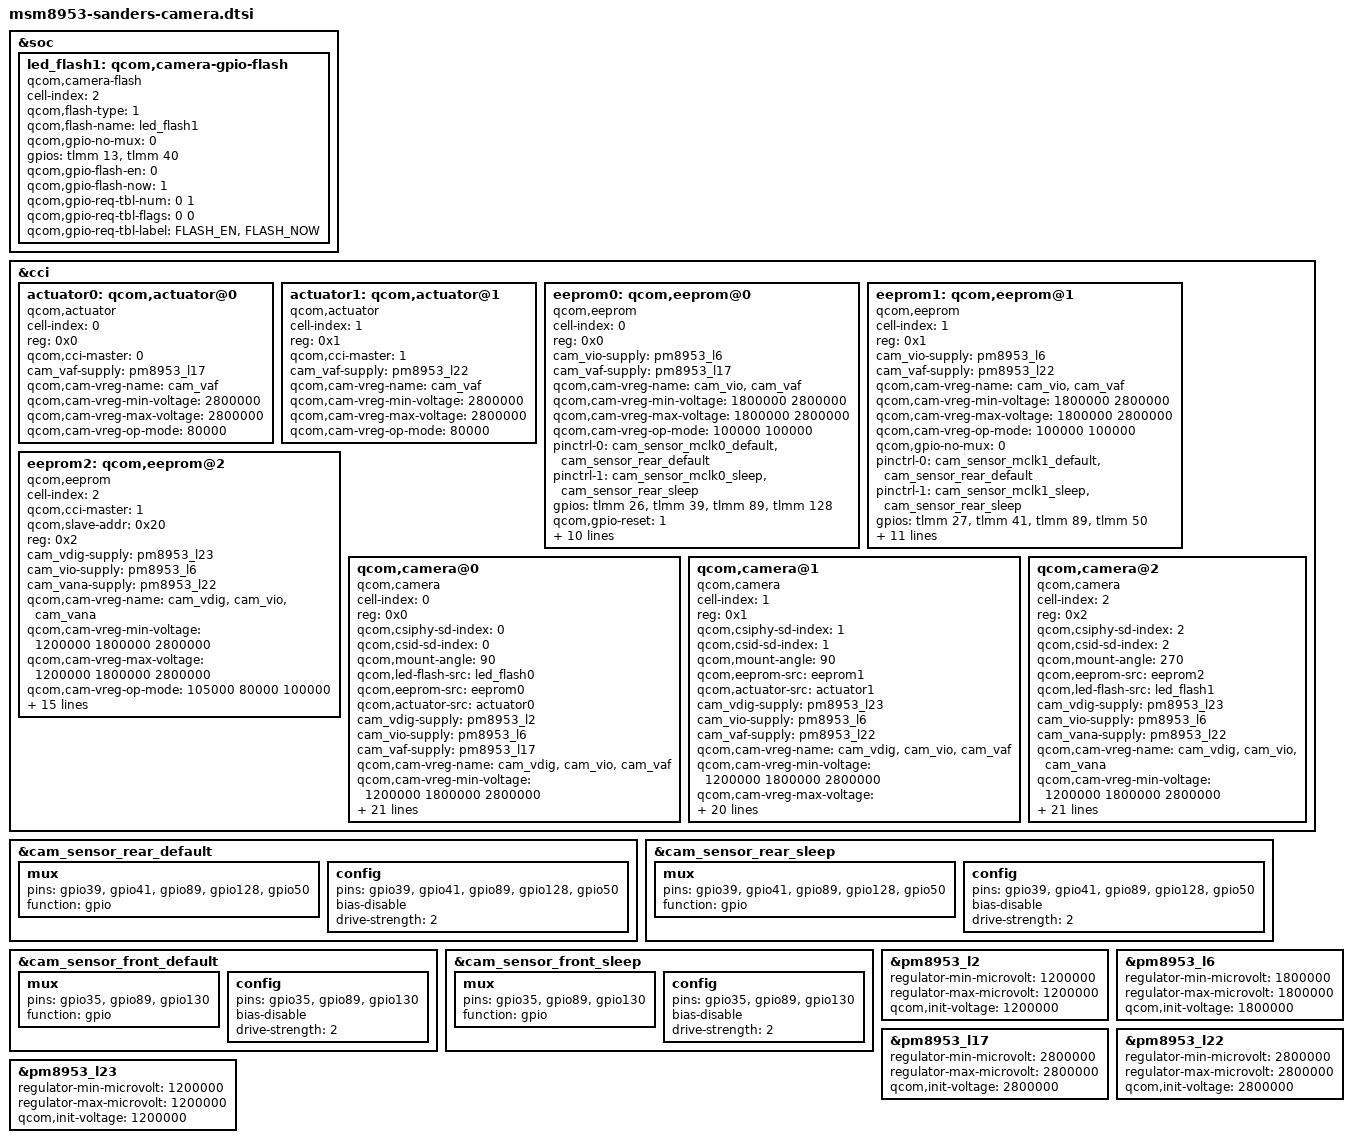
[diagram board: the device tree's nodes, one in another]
/*
 * Copyright (c) 2015-2016, The Linux Foundation. All rights reserved.
 *
 * This program is free software; you can redistribute it and/or modify
 * it under the terms of the GNU General Public License version 2 and
 * only version 2 as published by the Free Software Foundation.
 *
 * This program is distributed in the hope that it will be useful,
 * but WITHOUT ANY WARRANTY; without even the implied warranty of
 * MERCHANTABILITY or FITNESS FOR A PARTICULAR PURPOSE.  See the
 * GNU General Public License for more details.
 */

/*
 * Moto G5S Plus (sanders) cameras, ported from the Motorola 3.18
 * msm8953-camera-sensor-mot-sanders.dtsi to the 4.9 camera_v2 bindings:
 *   - rear:  2x S5K3L8 (bayer + mono) with actuators and eeproms
 *   - front: S5K4H8 with eeprom and a GPIO flash
 *   - rear flash: PMI8950 flash LEDs (led_flash0 from pmi8950.dtsi)
 *
 * Binding differences vs 3.18:
 *   - The CCI controller node comes from msm8953-camera.dtsi (identical).
 *   - The front GPIO flash used the Moto-only "qcom,camera-gpio-flash"
 *     driver. In 4.9 msm_flash.c handles GPIO flashes itself (driver type
 *     FLASH_DRIVER_GPIO when no PMIC source is given), so the node uses
 *     compatible "qcom,camera-flash" with qcom,gpio-flash-en/-now.
 *   - Camera pin groups already exist in msm8953-pinctrl.dtsi with
 *     different pins; only their pin lists are overridden here.
 */

&soc {
	led_flash1: qcom,camera-gpio-flash {
		cell-index = <2>;
		compatible = "qcom,camera-flash";
		qcom,flash-type = <1>;
		qcom,flash-name = "led_flash1";
		qcom,gpio-no-mux = <0>;
		gpios = <&tlmm 13 0>,
			<&tlmm 40 0>;
		qcom,gpio-flash-en = <0>;
		qcom,gpio-flash-now = <1>;
		qcom,gpio-req-tbl-num = <0 1>;
		qcom,gpio-req-tbl-flags = <0 0>;
		qcom,gpio-req-tbl-label = "FLASH_EN",
			"FLASH_NOW";
	};
};

&cci {
	#address-cells = <1>;
	#size-cells = <0>;

	actuator0: qcom,actuator@0 {
		cell-index = <0>;
		reg = <0x0>;
		compatible = "qcom,actuator";
		qcom,cci-master = <0>;
		cam_vaf-supply = <&pm8953_l17>;
		qcom,cam-vreg-name = "cam_vaf";
		qcom,cam-vreg-min-voltage = <2800000>;
		qcom,cam-vreg-max-voltage = <2800000>;
		qcom,cam-vreg-op-mode = <80000>;
	};

	actuator1: qcom,actuator@1 {
		cell-index = <1>;
		reg = <0x1>;
		compatible = "qcom,actuator";
		qcom,cci-master = <1>;
		cam_vaf-supply = <&pm8953_l22>;
		qcom,cam-vreg-name = "cam_vaf";
		qcom,cam-vreg-min-voltage = <2800000>;
		qcom,cam-vreg-max-voltage = <2800000>;
		qcom,cam-vreg-op-mode = <80000>;
	};

	/* S5K3L8 BEAR EEPROM*/
	eeprom0: qcom,eeprom@0 {
		cell-index = <0>;
		reg = <0x0>;
		compatible = "qcom,eeprom";
		cam_vio-supply = <&pm8953_l6>;
		cam_vaf-supply = <&pm8953_l17>;
		qcom,cam-vreg-name = "cam_vio", "cam_vaf";
		qcom,cam-vreg-min-voltage = <1800000 2800000>;
		qcom,cam-vreg-max-voltage = <1800000 2800000>;
		qcom,cam-vreg-op-mode = <100000 100000>;
		pinctrl-names = "cam_default", "cam_suspend";
		pinctrl-0 = <&cam_sensor_mclk0_default
				&cam_sensor_rear_default>;
		pinctrl-1 = <&cam_sensor_mclk0_sleep &cam_sensor_rear_sleep>;
		gpios = <&tlmm 26 0>,
			<&tlmm 39 0>,
			<&tlmm 89 0>,
			<&tlmm 128 0>;
		qcom,gpio-reset = <1>;
		qcom,gpio-vio = <2>;
		qcom,gpio-vana = <3>;
		qcom,gpio-req-tbl-num = <0 1 2 3>;
		qcom,gpio-req-tbl-flags = <1 0 0 0>;
		qcom,gpio-req-tbl-label = "CAMIF_MCLK0",
			"CAM_RESET0",
			"CAM_IO0",
			"CAM_VANA0";
		qcom,cci-master = <0>;
		status = "ok";
		clocks = <&clock_gcc clk_mclk0_clk_src>,
				<&clock_gcc clk_gcc_camss_mclk0_clk>;
		clock-names = "cam_src_clk", "cam_clk";
		qcom,clock-rates = <24000000 0>;
	};

	/* S5K3L8 MONO EEPROM */
	eeprom1: qcom,eeprom@1 {
		cell-index = <1>;
		reg = <0x1>;
		compatible = "qcom,eeprom";
		cam_vio-supply = <&pm8953_l6>;
		cam_vaf-supply = <&pm8953_l22>;
		qcom,cam-vreg-name = "cam_vio", "cam_vaf";
		qcom,cam-vreg-min-voltage = <1800000 2800000>;
		qcom,cam-vreg-max-voltage = <1800000 2800000>;
		qcom,cam-vreg-op-mode = <100000 100000>;
		qcom,gpio-no-mux = <0>;
		pinctrl-names = "cam_default", "cam_suspend";
		pinctrl-0 = <&cam_sensor_mclk1_default
				&cam_sensor_rear_default>;
		pinctrl-1 = <&cam_sensor_mclk1_sleep &cam_sensor_rear_sleep>;
		gpios = <&tlmm 27 0>,
			<&tlmm 41 0>,
			<&tlmm 89 0>,
			<&tlmm 50 0>;
		qcom,gpio-reset = <1>;
		qcom,gpio-vio = <2>;
		qcom,gpio-vana = <3>;
		qcom,gpio-req-tbl-num = <0 1 2 3>;
		qcom,gpio-req-tbl-flags = <1 0 0 0>;
		qcom,gpio-req-tbl-label = "CAMIF_MCLK1",
			"CAM_RESET1",
			"CAM_VIO1",
			"CAM_VANA1";
		qcom,cci-master = <1>;
		status = "ok";
		clocks = <&clock_gcc clk_mclk1_clk_src>,
				<&clock_gcc clk_gcc_camss_mclk1_clk>;
		clock-names = "cam_src_clk", "cam_clk";
		qcom,clock-rates = <24000000 0>;
	};

	/* L4H8F20 EEPROM*/
	eeprom2: qcom,eeprom@2 {
		cell-index = <2>;
		compatible = "qcom,eeprom";
		qcom,cci-master = <1>;
		qcom,slave-addr = <0x20>;
		reg = <0x2>;
		cam_vdig-supply = <&pm8953_l23>;
		cam_vio-supply = <&pm8953_l6>;
		cam_vana-supply = <&pm8953_l22>;
		qcom,cam-vreg-name = "cam_vdig", "cam_vio", "cam_vana";
		qcom,cam-vreg-min-voltage = <1200000 1800000 2800000>;
		qcom,cam-vreg-max-voltage = <1200000 1800000 2800000>;
		qcom,cam-vreg-op-mode = <105000 80000 100000>;
		pinctrl-names = "cam_default", "cam_suspend";
		pinctrl-0 = <&cam_sensor_mclk2_default
				&cam_sensor_front_default>;
		pinctrl-1 = <&cam_sensor_mclk2_sleep
				&cam_sensor_front_sleep>;
		gpios = <&tlmm 28 0>,
			<&tlmm 89 0>,
			<&tlmm 35 0>,
			<&tlmm 130 0>;
		qcom,gpio-vio = <1>;
		qcom,gpio-vana =<2>;
		qcom,gpio-standby = <3>;
		qcom,gpio-req-tbl-num = <0 1 2 3>;
		qcom,gpio-req-tbl-flags = <1 0 0 0>;
		qcom,gpio-req-tbl-label = "CAMIF_MCLK2",
			"CAM_VIO2",
			"CAM_VANA2",
			"CAM_STANDBY2";
		status = "ok";
		clocks = <&clock_gcc clk_mclk2_clk_src>,
				<&clock_gcc clk_gcc_camss_mclk2_clk>;
		clock-names = "cam_src_clk", "cam_clk";
		qcom,clock-rates = <24000000 0>;
	};

	/* S5K3L8 BEAR */
	qcom,camera@0 {
		cell-index = <0>;
		compatible = "qcom,camera";
		reg = <0x0>;
		qcom,csiphy-sd-index = <0>;
		qcom,csid-sd-index = <0>;
		qcom,mount-angle = <90>;
		qcom,led-flash-src = <&led_flash0>;
		qcom,eeprom-src = <&eeprom0>;
		qcom,actuator-src = <&actuator0>;
		cam_vdig-supply = <&pm8953_l2>;
		cam_vio-supply = <&pm8953_l6>;
		cam_vaf-supply = <&pm8953_l17>;
		qcom,cam-vreg-name = "cam_vdig", "cam_vio", "cam_vaf";
		qcom,cam-vreg-min-voltage = <1200000 1800000 2800000>;
		qcom,cam-vreg-max-voltage = <1200000 1800000 2800000>;
		qcom,cam-vreg-op-mode = <105000 100000 100000>;
		pinctrl-names = "cam_default", "cam_suspend";
		pinctrl-0 = <&cam_sensor_mclk0_default
				&cam_sensor_rear_default>;
		pinctrl-1 = <&cam_sensor_mclk0_sleep &cam_sensor_rear_sleep>;
		gpios = <&tlmm 26 0>,
			<&tlmm 39 0>,
			<&tlmm 89 0>,
			<&tlmm 128 0>;
		qcom,gpio-reset = <1>;
		qcom,gpio-vio = <2>;
		qcom,gpio-vana = <3>;
		qcom,gpio-req-tbl-num = <0 1 2 3>;
		qcom,gpio-req-tbl-flags = <1 0 0 0>;
		qcom,gpio-req-tbl-label = "CAMIF_MCLK0",
			"CAM_RESET0",
			"CAM_IO0",
			"CAM_VANA0";
		qcom,sensor-position = <0>;
		qcom,sensor-mode = <0>;
		qcom,cci-master = <0>;
		status = "ok";
		clocks = <&clock_gcc clk_mclk0_clk_src>,
				<&clock_gcc clk_gcc_camss_mclk0_clk>;
		clock-names = "cam_src_clk", "cam_clk";
		qcom,clock-rates = <24000000 0>;
	};

	/* S5K3L8 MONO */
	qcom,camera@1 {
		cell-index = <1>;
		compatible = "qcom,camera";
		reg = <0x1>;
		qcom,csiphy-sd-index = <1>;
		qcom,csid-sd-index = <1>;
		qcom,mount-angle = <90>;
		qcom,eeprom-src = <&eeprom1>;
		qcom,actuator-src = <&actuator1>;
		cam_vdig-supply = <&pm8953_l23>;
		cam_vio-supply = <&pm8953_l6>;
		cam_vaf-supply = <&pm8953_l22>;
		qcom,cam-vreg-name = "cam_vdig", "cam_vio", "cam_vaf";
		qcom,cam-vreg-min-voltage = <1200000 1800000 2800000>;
		qcom,cam-vreg-max-voltage = <1200000 1800000 2800000>;
		qcom,cam-vreg-op-mode = <105000 100000 100000>;
		pinctrl-names = "cam_default", "cam_suspend";
		pinctrl-0 = <&cam_sensor_mclk1_default
				&cam_sensor_rear_default>;
		pinctrl-1 = <&cam_sensor_mclk1_sleep &cam_sensor_rear_sleep>;
		gpios = <&tlmm 27 0>,
			<&tlmm 41 0>,
			<&tlmm 89 0>,
			<&tlmm 50 0>;
		qcom,gpio-reset = <1>;
		qcom,gpio-vio = <2>;
		qcom,gpio-vana = <3>;
		qcom,gpio-req-tbl-num = <0 1 2 3>;
		qcom,gpio-req-tbl-flags = <1 0 0 0>;
		qcom,gpio-req-tbl-label = "CAMIF_MCLK1",
			"CAM_RESET1",
			"CAM_VIO1",
			"CAM_VANA1";
		qcom,sensor-position = <0>;
		qcom,sensor-mode = <0>;
		qcom,cci-master = <1>;
		status = "ok";
		clocks = <&clock_gcc clk_mclk1_clk_src>,
				<&clock_gcc clk_gcc_camss_mclk1_clk>;
		clock-names = "cam_src_clk", "cam_clk";
		qcom,clock-rates = <24000000 0>;
	};

	/* S5K4H8 */
	qcom,camera@2 {
		cell-index = <2>;
		compatible = "qcom,camera";
		reg = <0x2>;
		qcom,csiphy-sd-index = <2>;
		qcom,csid-sd-index = <2>;
		qcom,mount-angle = <270>;
		qcom,eeprom-src = <&eeprom2>;
		qcom,led-flash-src = <&led_flash1>;
		cam_vdig-supply = <&pm8953_l23>;
		cam_vio-supply = <&pm8953_l6>;
		cam_vana-supply = <&pm8953_l22>;
		qcom,cam-vreg-name = "cam_vdig", "cam_vio", "cam_vana";
		qcom,cam-vreg-min-voltage = <1200000 1800000 2800000>;
		qcom,cam-vreg-max-voltage = <1200000 1800000 2800000>;
		qcom,cam-vreg-op-mode = <105000 80000 100000>;
		pinctrl-names = "cam_default", "cam_suspend";
		pinctrl-0 = <&cam_sensor_mclk2_default
				&cam_sensor_front_default>;
		pinctrl-1 = <&cam_sensor_mclk2_sleep
				&cam_sensor_front_sleep>;
		gpios = <&tlmm 28 0>,
			<&tlmm 89 0>,
			<&tlmm 35 0>,
			<&tlmm 130 0>;
		qcom,gpio-vio = <1>;
		qcom,gpio-vana =<2>;
		qcom,gpio-standby = <3>;
		qcom,gpio-req-tbl-num = <0 1 2 3>;
		qcom,gpio-req-tbl-flags = <1 0 0 0>;
		qcom,gpio-req-tbl-label = "CAMIF_MCLK2",
			"CAM_VIO2",
			"CAM_VANA2",
			"CAM_STANDBY2";
		qcom,sensor-position = <1>;
		qcom,sensor-mode = <0>;
		qcom,cci-master = <1>;
		status = "ok";
		clocks = <&clock_gcc clk_mclk2_clk_src>,
				<&clock_gcc clk_gcc_camss_mclk2_clk>;
		clock-names = "cam_src_clk", "cam_clk";
		qcom,clock-rates = <24000000 0>;
	};

};

&cam_sensor_rear_default {
	/* RESET0, RESET1, VIO, VANA0, VANA1 */
	mux {
		pins = "gpio39", "gpio41", "gpio89", "gpio128", "gpio50";
		function = "gpio";
	};

	config {
		pins = "gpio39", "gpio41", "gpio89", "gpio128", "gpio50";
		bias-disable;
		drive-strength = <2>;
	};
};

&cam_sensor_rear_sleep {
	mux {
		pins = "gpio39", "gpio41", "gpio89", "gpio128", "gpio50";
		function = "gpio";
	};

	config {
		pins = "gpio39", "gpio41", "gpio89", "gpio128", "gpio50";
		bias-disable;
		drive-strength = <2>;
	};
};

&cam_sensor_front_default {
	/* VIO, VANA, STANDBY */
	mux {
		pins = "gpio35", "gpio89", "gpio130";
		function = "gpio";
	};

	config {
		pins = "gpio35", "gpio89", "gpio130";
		bias-disable;
		drive-strength = <2>;
	};
};

&cam_sensor_front_sleep {
	mux {
		pins = "gpio35", "gpio89", "gpio130";
		function = "gpio";
	};

	config {
		pins = "gpio35", "gpio89", "gpio130";
		bias-disable;
		drive-strength = <2>;
	};
};

/* Camera rails (from the 3.18 camera dtsi rpm_bus overrides) */
&pm8953_l2 {
	regulator-min-microvolt = <1200000>;
	regulator-max-microvolt = <1200000>;
	qcom,init-voltage = <1200000>;
	status = "okay";
};

&pm8953_l6 {
	regulator-min-microvolt = <1800000>;
	regulator-max-microvolt = <1800000>;
	qcom,init-voltage = <1800000>;
	status = "okay";
};

&pm8953_l17 {
	regulator-min-microvolt = <2800000>;
	regulator-max-microvolt = <2800000>;
	qcom,init-voltage = <2800000>;
	status = "okay";
};

&pm8953_l22 {
	regulator-min-microvolt = <2800000>;
	regulator-max-microvolt = <2800000>;
	qcom,init-voltage = <2800000>;
	status = "okay";
};

&pm8953_l23 {
	regulator-min-microvolt = <1200000>;
	regulator-max-microvolt = <1200000>;
	qcom,init-voltage = <1200000>;
	status = "okay";
};
